# STM32U356 register map
File version: 1.0
CPU: CM33 r0p1, little endian, MPU, FPU, 4 interrupt priority bits
Registers are 32-bit, read-write, reset 0x0 unless marked. A register's access mark holds for its fields unless they carry their own. Offsets are from the block's base; [hi:lo] are bit positions; {n}, {i} and the like mark numbered series; 'fields as' and 'values as' point back to an identical list.

## LCD — Liquid crystal display controller
Base 0x40048000
Same registers: SEC_LCD 0x50048000
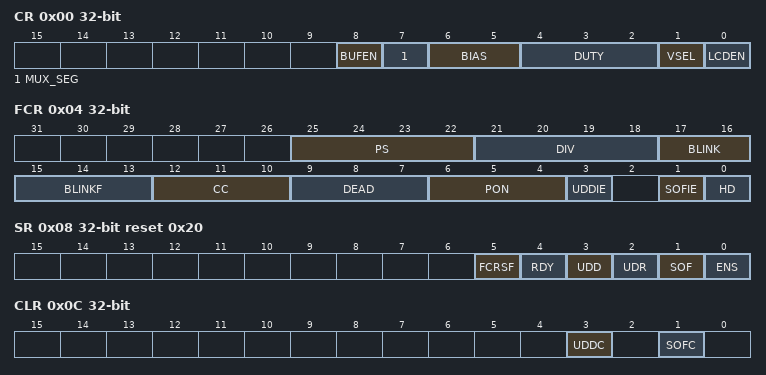
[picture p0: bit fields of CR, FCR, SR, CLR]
0x00 CR — control register
  [8] BUFEN — Voltage output buffer enable
  [7] MUX_SEG — Mux segment enable
  [6:5] BIAS — Bias selector
  [4:2] DUTY — Duty selection
  [1] VSEL — Voltage source selection
  [0] LCDEN — LCD controller enable
0x04 FCR — frame control register
  [25:22] PS — PS 16-bit prescaler
  [21:18] DIV — DIV clock divider
  [17:16] BLINK — Blink mode selection
  [15:13] BLINKF — Blink frequency selection
  [12:10] CC — Contrast control
  [9:7] DEAD — Dead time duration
  [6:4] PON — Pulse ON duration
  [3] UDDIE — Update display done interrupt enable
  [1] SOFIE — Start of frame interrupt enable
  [0] HD — High drive enable
0x08 SR access per field reset 0x20 — status register
  [5] FCRSF ro — LCD Frame Control Register Synchronization flag
  [4] RDY ro — Ready flag
  [3] UDD ro — Update Display Done
  [2] UDR wo — Update display request
  [1] SOF ro — Start of frame flag
  [0] ENS ro
0x0C CLR wo — clear register
  [3] UDDC — Update display done clear
  [1] SOFC — Start of frame flag clear
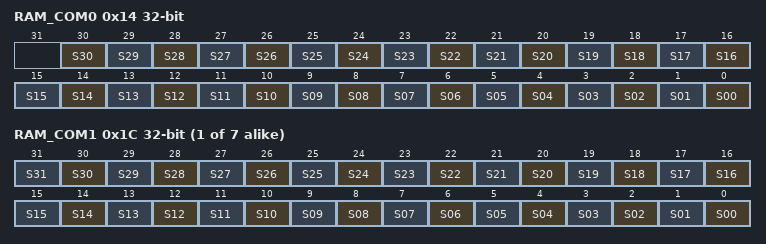
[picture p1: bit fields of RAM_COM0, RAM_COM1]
0x14 RAM_COM0 — display memory
  [n] S{n:02} (n=0..30)
{0x14+8i} RAM_COM{i} (i=1..7) — display memory
  [n] S{n:02} (n=0..31)

## OPAMP — OPAMP Address block
Base 0x40007000
Same registers: SEC_OPAMP 0x50007000
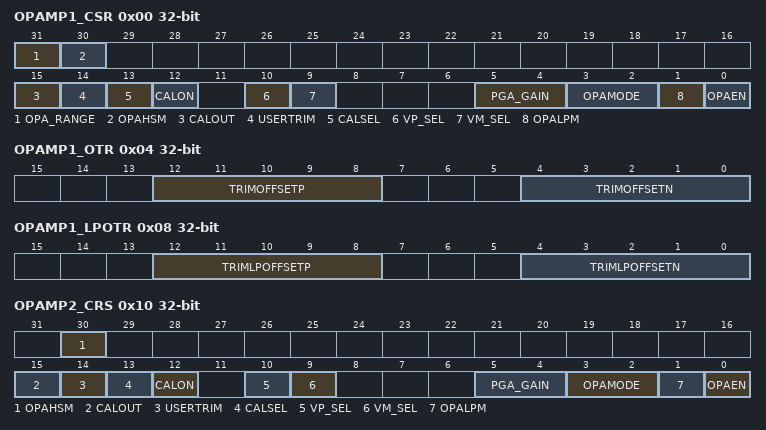
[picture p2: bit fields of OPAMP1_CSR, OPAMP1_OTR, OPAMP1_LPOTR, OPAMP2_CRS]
0x00 OPAMP1_CSR — OPAMP1 control/status register
  [31] OPA_RANGE — OPAMP range setting
    1=OPAMP range set
  [30] OPAHSM — OPAMP high-speed mode
    0=Normal mode (standard slew rate); 1=Increased consumption to improve the slew rate
  [15] CALOUT ro — OPAMP calibration output
  [14] USERTRIM — Selection of factory or user offset trimmed values
    0=Factory trim code used; 1=User trim code used
  [13] CALSEL — Calibration selection
    0=NMOS calibration (200mV applied on OPAMP inputs); 1=PMOS calibration (Vless thansub>DDA less than/sub>- 200 mV applied on OPAMP inputs)
  [12] CALON — Calibration mode enable
    0=Normal mode; 1=Calibration mode (all switches opened by hardware)
  [10] VP_SEL — Noninverted input selection
    0=GPIO connected to VINP; 1=DAC connected to VINP
  [9] VM_SEL — Inverting input selection
    0=GPIO connected to VINM (valid also in PGA mode for filtering); 1=Inverting input not externally connected
  [5:4] PGA_GAIN — OPAMP programmable amplifier gain value
    0=Internal PGA gain 2; 1=Internal PGA gain 4; 2=Internal PGA gain 8; 3=Internal PGA gain 16
  [3:2] OPAMODE — OPAMP PGA mode
    0=Internal PGA disabled; 1=Internal PGA disabled; 2=Internal PGA enabled, gain programmed in PGA_GAIN; 3=Internal follower
  [1] OPALPM — OPAMP low-power mode
    0=Normal mode; 1=Low-power mode
  [0] OPAEN — OPAMP enable
    0=OPAMP disabled; 1=OPAMP enabled
0x04 OPAMP1_OTR (reset mask 0xFFFF0000) — OPAMP1 offset trimming register in normal mode
  [12:8] TRIMOFFSETP — Trim for PMOS differential pairs
  [4:0] TRIMOFFSETN — Trim for NMOS differential pairs
0x08 OPAMP1_LPOTR (reset mask 0xFFFF0000) — OPAMP1 offset trimming register in low-power mode
  [12:8] TRIMLPOFFSETP — Low-power mode trim for PMOS differential pairs
  [4:0] TRIMLPOFFSETN — Low-power mode trim for NMOS differential pairs
0x10 OPAMP2_CRS — OPAMP2 control/status register
  [30] OPAHSM — OPAMP high-speed mode
    values as OPAMP1_CSR.OPAHSM
  [15] CALOUT ro — OPAMP calibration output
  [14] USERTRIM — Selection of factory or user offset trimmed values
    0=Factory trim code used; 1=User trim code used
  [13] CALSEL — Calibration selection
    0=NMOS calibration (200 mV applied on OPAMP inputs); 1=PMOS calibration (Vless thansub>DDA less than/sub>- 200 mV applied on OPAMP inputs)
  [12] CALON — Calibration mode enable
    values as OPAMP1_CSR.CALON
  [10] VP_SEL — Noninverted input selection
    0=GPIO connected to VINP; 1=DAC connected to VINP
  [9] VM_SEL — Inverting input selection
    values as OPAMP1_CSR.VM_SEL
  [5:4] PGA_GAIN — OPAMP programmable amplifier gain value
    values as OPAMP1_CSR.PGA_GAIN
  [3:2] OPAMODE — OPAMP PGA mode
    0=internal PGA disabled; 1=internal PGA disabled; 2=Internal PGA enabled, gain programmed in PGA_GAIN; 3=Internal follower
  [1] OPALPM — OPAMP low-power mode
    0=Normal mode; 1=Low-power mode
  [0] OPAEN — OPAMP enable
    0=OPAMP disabled; 1=OPAMP enabled
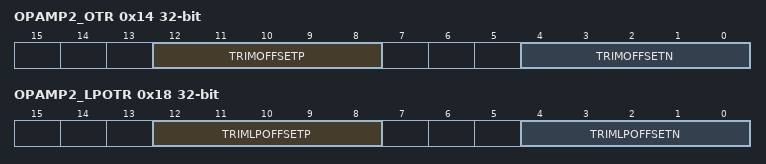
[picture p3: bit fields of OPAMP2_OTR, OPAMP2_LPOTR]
0x14 OPAMP2_OTR (reset mask 0xFFFF0000) — OPAMP2 offset trimming register in normal mode
  fields as OPAMP1_OTR
0x18 OPAMP2_LPOTR (reset mask 0xFFFF0000) — OPAMP2 offset trimming register in low-power mode
  fields as OPAMP1_LPOTR
